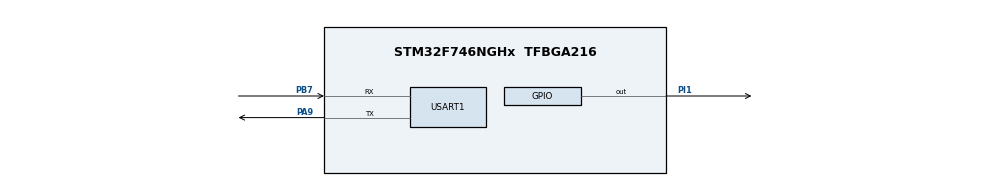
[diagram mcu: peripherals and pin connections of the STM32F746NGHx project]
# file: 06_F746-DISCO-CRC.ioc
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CRC.InputDataFormat=CRC_INPUTDATA_FORMAT_WORDS
Mcu.Family=STM32F7
Mcu.Name=STM32F746NGHx
Mcu.Package=TFBGA216
NVIC.PriorityGroup=NVIC_PRIORITYGROUP_4
PA9.Mode=Asynchronous
PA9.Signal=USART1_TX
PB7.Mode=Asynchronous
PB7.Signal=USART1_RX
PI1.Signal=GPIO_Output
ProjectManager.HeapSize=0x200
ProjectManager.StackSize=0x400
ProjectManager.TargetToolchain=STM32CubeIDE
RCC.HSE_VALUE=25000000
RCC.HSI_VALUE=16000000
RCC.LSE_VALUE=32768
RCC.USBFreq_Value=96000000
RCC.VCOOutputFreq_Value=192000000
USART1.VirtualMode-Asynchronous=VM_ASYNC
VP_CRC_VS_CRC.Mode=CRC_Activate
board=STM32F746G-DISCO

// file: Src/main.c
/* USER CODE BEGIN Header */
/**
  ******************************************************************************
  * @file           : main.c
  * @brief          : Main program body
  ******************************************************************************
  * @attention
  *
  * <h2><center>&copy; Copyright (c) 2019 STMicroelectronics.
  * All rights reserved.</center></h2>
  *
  * This software component is licensed by ST under BSD 3-Clause license,
  * the "License"; You may not use this file except in compliance with the
  * License. You may obtain a copy of the License at:
  *                        opensource.org/licenses/BSD-3-Clause
  *
  ******************************************************************************
  */
/* USER CODE END Header */

#include "main.h"

/* USER CODE BEGIN Includes */
#include <stdio.h>
/* USER CODE END Includes */

CRC_HandleTypeDef hcrc;

UART_HandleTypeDef huart1;

void SystemClock_Config(void);
static void MX_GPIO_Init(void);
static void MX_USART1_UART_Init(void);
static void MX_CRC_Init(void);
/* USER CODE BEGIN PFP */
uint32_t Crc32(uint32_t Crc, uint32_t Data);

/* USER CODE END PFP */

/* USER CODE BEGIN 0 */
#ifdef BUFFER_SIZE_0x4000
#define BUFFER_SIZE	(0x4000 - 4)/4
#else
#define BUFFER_SIZE	(0x8000 - 4)/4
#endif

__IO uint32_t uwCRCValue = 0;
__IO uint32_t myCRCValue1 = 0xFFFFFFFF;

const uint32_t *myDataBuffer;

/* USER CODE END 0 */

int main(void)
{
  /* USER CODE BEGIN 1 */
  uint16_t myDataBufferCount = BUFFER_SIZE;
  myDataBuffer = (uint32_t*) 0x08000000;

  /* USER CODE END 1 */

  /* MCU Configuration--------------------------------------------------------*/

  /* Reset of all peripherals, Initializes the Flash interface and the Systick. */
  HAL_Init();

  /* Configure the system clock */
  SystemClock_Config();

  /* Initialize all configured peripherals */
  MX_GPIO_Init();
  MX_USART1_UART_Init();
  MX_CRC_Init();
  /* USER CODE BEGIN 2 */
  printf("\n\rCRC TEST\n\r");

  /*##-1- Compute the CRC by STM32 CRC peripheral ###################################*/
  //uwCRCValue = HAL_CRC_Calculate(&hcrc, (uint32_t *)0x08000000, BUFFER_SIZE);
  uwCRCValue = HAL_CRC_Accumulate(&hcrc, (uint32_t *)0x08000000, BUFFER_SIZE);
  //uwCRCValue = MY_HAL_CRC_Calculate(&hcrc, (uint8_t *)0x08000000, BUFFER_SIZE_BYTE);

  /*##-2- Compute the CRC of "myDataBuffer" by Crc32 SW Code###################################*/
  while (myDataBufferCount--)
  {
    myCRCValue1 = Crc32(myCRCValue1, *myDataBuffer++);
  }
  printf("\n\n\r========================================Display Final Result========================================\n\r");
  printf("uwCRCValue generated by STM32 CRC Unit= 0x%08X\n\r",(unsigned int) uwCRCValue);	//shut compiling warning up
  printf("myCRCValue1 generated by Crc32 SW code= 0x%08X\n\r",(unsigned int) myCRCValue1);	//shut compiling warning up

#ifdef BUFFER_SIZE_0x4000
  if (uwCRCValue == *(uint32_t*)0x08003FFC)
#else
  if (uwCRCValue == *(uint32_t*)0x08007FFC)
#endif
  {
    printf("CRC Check: OK...\n\r");
  }
  else
  {
    printf("CRC Check: Fail...\n\r");
  }
  printf("\tChecksum generated by STM32 CRC Unit= 0x%08X\n\r",(unsigned int) uwCRCValue);

#ifdef BUFFER_SIZE_0x4000
  printf("\tChecksum stored at address 0x08003FFC= 0x%08X\n\r",*(uint32_t*)0x08003FFC);
#else
  printf("\tChecksum stored at address 0x08007FFC= 0x%08X\n\r",*(unsigned int*)0x08007FFC);
#endif

  /* USER CODE END 2 */

  /* Infinite loop */
  while (1)
  {

    /* USER CODE BEGIN 3 */
    //HAL_Delay(500);
    //HAL_GPIO_TogglePin(GPIOI, GPIO_PIN_1);
    //printf("LD1: %d\n\r", HAL_GPIO_ReadPin(GPIOI, GPIO_PIN_1));
  }
  /* USER CODE END 3 */
}

void SystemClock_Config(void)
{
  RCC_OscInitTypeDef RCC_OscInitStruct = {0};
  RCC_ClkInitTypeDef RCC_ClkInitStruct = {0};
  RCC_PeriphCLKInitTypeDef PeriphClkInitStruct = {0};

  /** Configure the main internal regulator output voltage
  */
  __HAL_RCC_PWR_CLK_ENABLE();
  __HAL_PWR_VOLTAGESCALING_CONFIG(PWR_REGULATOR_VOLTAGE_SCALE3);
  /** Initializes the CPU, AHB and APB busses clocks
  */
  RCC_OscInitStruct.OscillatorType = RCC_OSCILLATORTYPE_HSI;
  RCC_OscInitStruct.HSIState = RCC_HSI_ON;
  RCC_OscInitStruct.HSICalibrationValue = RCC_HSICALIBRATION_DEFAULT;
  RCC_OscInitStruct.PLL.PLLState = RCC_PLL_NONE;
  if (HAL_RCC_OscConfig(&RCC_OscInitStruct) != HAL_OK)
  {
    Error_Handler();
  }
  /** Initializes the CPU, AHB and APB busses clocks
  */
  RCC_ClkInitStruct.ClockType = RCC_CLOCKTYPE_HCLK|RCC_CLOCKTYPE_SYSCLK
                              |RCC_CLOCKTYPE_PCLK1|RCC_CLOCKTYPE_PCLK2;
  RCC_ClkInitStruct.SYSCLKSource = RCC_SYSCLKSOURCE_HSI;
  RCC_ClkInitStruct.AHBCLKDivider = RCC_SYSCLK_DIV1;
  RCC_ClkInitStruct.APB1CLKDivider = RCC_HCLK_DIV1;
  RCC_ClkInitStruct.APB2CLKDivider = RCC_HCLK_DIV1;

  if (HAL_RCC_ClockConfig(&RCC_ClkInitStruct, FLASH_LATENCY_0) != HAL_OK)
  {
    Error_Handler();
  }
  PeriphClkInitStruct.PeriphClockSelection = RCC_PERIPHCLK_USART1;
  PeriphClkInitStruct.Usart1ClockSelection = RCC_USART1CLKSOURCE_PCLK2;
  if (HAL_RCCEx_PeriphCLKConfig(&PeriphClkInitStruct) != HAL_OK)
  {
    Error_Handler();
  }
}

static void MX_CRC_Init(void)
{

  hcrc.Instance = CRC;
  hcrc.Init.DefaultPolynomialUse = DEFAULT_POLYNOMIAL_ENABLE;
  hcrc.Init.DefaultInitValueUse = DEFAULT_INIT_VALUE_ENABLE;
  hcrc.Init.InputDataInversionMode = CRC_INPUTDATA_INVERSION_NONE;
  hcrc.Init.OutputDataInversionMode = CRC_OUTPUTDATA_INVERSION_DISABLE;
  hcrc.InputDataFormat = CRC_INPUTDATA_FORMAT_WORDS;
  if (HAL_CRC_Init(&hcrc) != HAL_OK)
  {
    Error_Handler();
  }

}

static void MX_USART1_UART_Init(void)
{

  huart1.Instance = USART1;
  huart1.Init.BaudRate = 115200;
  huart1.Init.WordLength = UART_WORDLENGTH_8B;
  huart1.Init.StopBits = UART_STOPBITS_1;
  huart1.Init.Parity = UART_PARITY_NONE;
  huart1.Init.Mode = UART_MODE_TX_RX;
  huart1.Init.HwFlowCtl = UART_HWCONTROL_NONE;
  huart1.Init.OverSampling = UART_OVERSAMPLING_16;
  huart1.Init.OneBitSampling = UART_ONE_BIT_SAMPLE_DISABLE;
  huart1.AdvancedInit.AdvFeatureInit = UART_ADVFEATURE_NO_INIT;
  if (HAL_UART_Init(&huart1) != HAL_OK)
  {
    Error_Handler();
  }

}

static void MX_GPIO_Init(void)
{
  GPIO_InitTypeDef GPIO_InitStruct = {0};

  /* GPIO Ports Clock Enable */
  __HAL_RCC_GPIOB_CLK_ENABLE();
  __HAL_RCC_GPIOI_CLK_ENABLE();
  __HAL_RCC_GPIOA_CLK_ENABLE();

  /*Configure GPIO pin Output Level */
  HAL_GPIO_WritePin(GPIOI, GPIO_PIN_1, GPIO_PIN_RESET);

  /*Configure GPIO pin : PI1 */
  GPIO_InitStruct.Pin = GPIO_PIN_1;
  GPIO_InitStruct.Mode = GPIO_MODE_OUTPUT_PP;
  GPIO_InitStruct.Pull = GPIO_NOPULL;
  GPIO_InitStruct.Speed = GPIO_SPEED_FREQ_LOW;
  HAL_GPIO_Init(GPIOI, &GPIO_InitStruct);

}

/* USER CODE BEGIN 4 */
int __io_putchar(int ch)
{
  HAL_UART_Transmit(&huart1, (uint8_t *)&ch, 1, 0xFFFF);
  return ch;
}

uint32_t Crc32(uint32_t Crc, uint32_t Data)
{
  uint8_t index;
#ifdef VERBOSE_PRINTF_CRC32
  printf("\n\rPREPARATION\tINIT_CRC=0x%08X\tDATA=0x%08X\t", Crc, Data);
#endif
  Crc = Crc ^ Data;
#ifdef VERBOSE_PRINTF_CRC32
  printf("NEW CRC=0x%8X\n\r", Crc);
#endif

  for(index=0; index<32; index++)
  {
#ifdef VERBOSE_PRINTF_CRC32
    printf("Index=%2d\tINIT_CRC=0x%08X\tPOLY=0x04C11DB7\t",index,Crc);
#endif
    if (Crc & 0x80000000)
      Crc = (Crc << 1) ^ 0x04C11DB7; // Polynomial used in STM32
    else
      Crc = (Crc << 1);
#ifdef VERBOSE_PRINTF_CRC32
    printf("NEW CRC=0x%08X\n\r",Crc);
#endif
  }
  return(Crc);
}

/* USER CODE END 4 */

void Error_Handler(void)
{
}

/************************ (C) COPYRIGHT STMicroelectronics *****END OF FILE****/
